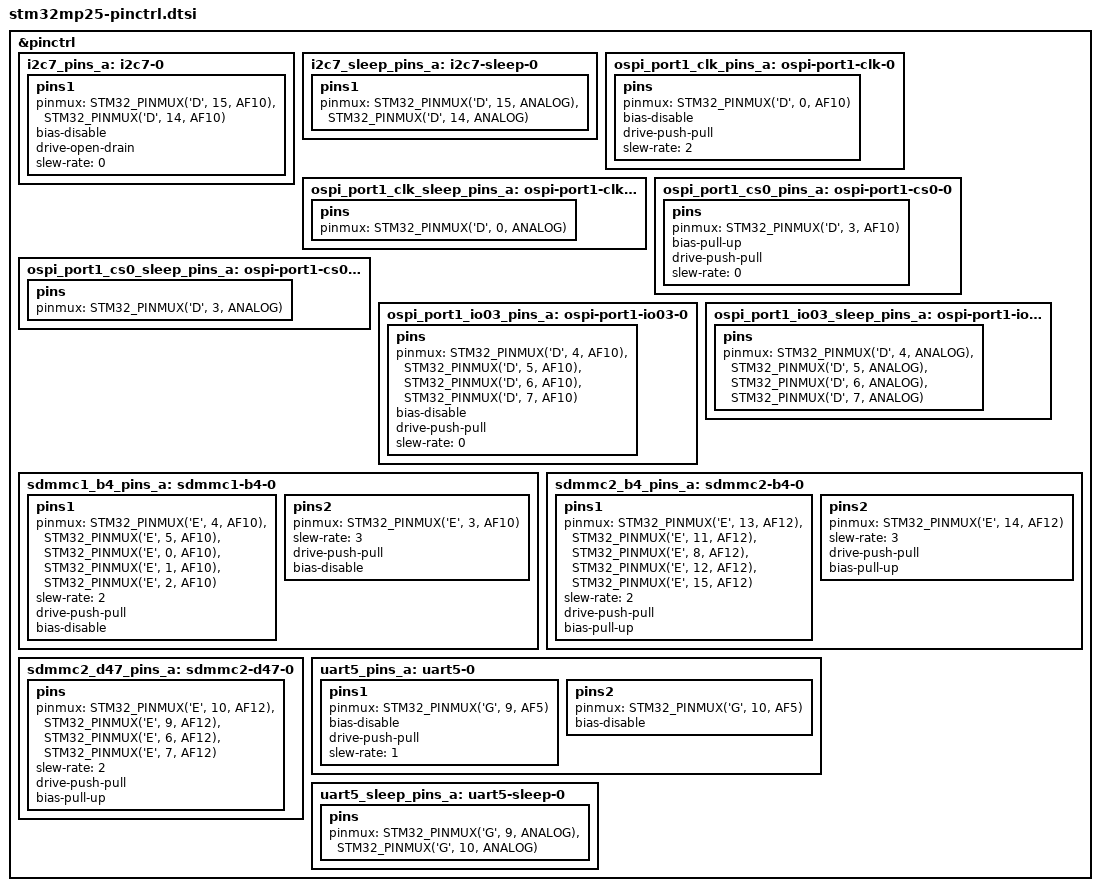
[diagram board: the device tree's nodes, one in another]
/*
 * Copyright (c) 2026, STMicroelectronics - All Rights Reserved
 *
 * SPDX-License-Identifier: Apache-2.0
 */
#include <dt-bindings/pinctrl/stm32-pinfunc.h>

&pinctrl {
	i2c7_pins_a: i2c7-0 {
		pins1 {
			pinmux = <STM32_PINMUX('D', 15, AF10)>, /* I2C7_SCL */
				 <STM32_PINMUX('D', 14, AF10)>; /* I2C7_SDA */
			bias-disable;
			drive-open-drain;
			slew-rate = <0>;
		};
	};

	i2c7_sleep_pins_a: i2c7-sleep-0 {
		pins1 {
			pinmux = <STM32_PINMUX('D', 15, ANALOG)>, /* I2C7_SCL */
				 <STM32_PINMUX('D', 14, ANALOG)>; /* I2C7_SDA */
		};
	};

	ospi_port1_clk_pins_a: ospi-port1-clk-0 {
		pins {
			pinmux = <STM32_PINMUX('D', 0, AF10)>; /* OSPI_CLK */
			bias-disable;
			drive-push-pull;
			slew-rate = <2>;
		};
	};

	ospi_port1_clk_sleep_pins_a: ospi-port1-clk-sleep-0 {
		pins {
			pinmux = <STM32_PINMUX('D', 0, ANALOG)>; /* OSPI_CLK */
		};
	};

	ospi_port1_cs0_pins_a: ospi-port1-cs0-0 {
		pins {
			pinmux = <STM32_PINMUX('D', 3, AF10)>; /* OSPI_NCS0 */
			bias-pull-up;
			drive-push-pull;
			slew-rate = <0>;
		};
	};

	ospi_port1_cs0_sleep_pins_a: ospi-port1-cs0-sleep-0 {
		pins {
			pinmux = <STM32_PINMUX('D', 3, ANALOG)>; /* OSPI_NCS0 */
		};
	};

	ospi_port1_io03_pins_a: ospi-port1-io03-0 {
		pins {
			pinmux = <STM32_PINMUX('D', 4, AF10)>, /* OSPI_IO0 */
				 <STM32_PINMUX('D', 5, AF10)>, /* OSPI_IO1 */
				 <STM32_PINMUX('D', 6, AF10)>, /* OSPI_IO2 */
				 <STM32_PINMUX('D', 7, AF10)>; /* OSPI_IO3 */
			bias-disable;
			drive-push-pull;
			slew-rate = <0>;
		};
	};

	ospi_port1_io03_sleep_pins_a: ospi-port1-io03-sleep-0 {
		pins {
			pinmux = <STM32_PINMUX('D', 4, ANALOG)>, /* OSPI_IO0 */
				 <STM32_PINMUX('D', 5, ANALOG)>, /* OSPI_IO1 */
				 <STM32_PINMUX('D', 6, ANALOG)>, /* OSPI_IO2 */
				 <STM32_PINMUX('D', 7, ANALOG)>; /* OSPI_IO3 */
		};
	};

	sdmmc1_b4_pins_a: sdmmc1-b4-0 {
		pins1 {
			pinmux = <STM32_PINMUX('E', 4, AF10)>, /* SDMMC1_D0 */
				 <STM32_PINMUX('E', 5, AF10)>, /* SDMMC1_D1 */
				 <STM32_PINMUX('E', 0, AF10)>, /* SDMMC1_D2 */
				 <STM32_PINMUX('E', 1, AF10)>, /* SDMMC1_D3 */
				 <STM32_PINMUX('E', 2, AF10)>; /* SDMMC1_CMD */
			slew-rate = <2>;
			drive-push-pull;
			bias-disable;
		};
		pins2 {
			pinmux = <STM32_PINMUX('E', 3, AF10)>; /* SDMMC1_CK */
			slew-rate = <3>;
			drive-push-pull;
			bias-disable;
		};
	};

	sdmmc2_b4_pins_a: sdmmc2-b4-0 {
		pins1 {
			pinmux = <STM32_PINMUX('E', 13, AF12)>, /* SDMMC2_D0 */
				 <STM32_PINMUX('E', 11, AF12)>, /* SDMMC2_D1 */
				 <STM32_PINMUX('E', 8, AF12)>, /* SDMMC2_D2 */
				 <STM32_PINMUX('E', 12, AF12)>, /* SDMMC2_D3 */
				 <STM32_PINMUX('E', 15, AF12)>; /* SDMMC2_CMD */
			slew-rate = <2>;
			drive-push-pull;
			bias-pull-up;
		};
		pins2 {
			pinmux = <STM32_PINMUX('E', 14, AF12)>; /* SDMMC2_CK */
			slew-rate = <3>;
			drive-push-pull;
			bias-pull-up;
		};
	};

	sdmmc2_d47_pins_a: sdmmc2-d47-0 {
		pins {
			pinmux = <STM32_PINMUX('E', 10, AF12)>, /* SDMMC2_D4 */
				 <STM32_PINMUX('E', 9, AF12)>, /* SDMMC2_D5 */
				 <STM32_PINMUX('E', 6, AF12)>, /* SDMMC2_D6 */
				 <STM32_PINMUX('E', 7, AF12)>; /* SDMMC2_D7 */
			slew-rate = <2>;
			drive-push-pull;
			bias-pull-up;
		};
	};

	uart5_pins_a: uart5-0 {
		pins1 {
			pinmux = <STM32_PINMUX('G', 9, AF5)>; /* UART5_TX */
			bias-disable;
			drive-push-pull;
			slew-rate = <1>;
		};
		pins2 {
			pinmux = <STM32_PINMUX('G', 10, AF5)>; /* UART5_RX */
			bias-disable;
		};
	};

	uart5_sleep_pins_a: uart5-sleep-0 {
		pins {
			pinmux = <STM32_PINMUX('G', 9, ANALOG)>, /* UART5_TX */
				 <STM32_PINMUX('G', 10, ANALOG)>; /* UART5_RX */
		};
	};
};
